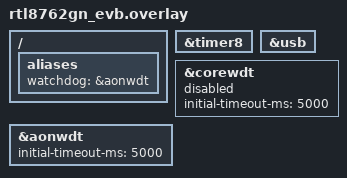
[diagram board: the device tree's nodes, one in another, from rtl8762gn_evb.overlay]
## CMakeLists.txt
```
# SPDX-License-Identifier: Apache-2.0

cmake_minimum_required(VERSION 3.20.0)
find_package(Zephyr REQUIRED HINTS $ENV{ZEPHYR_BASE})
project(ppt_dongle)

FILE(GLOB app_sources src/*.c)
list(REMOVE_ITEM app_sources ${CMAKE_CURRENT_SOURCE_DIR}/src/dongle_ppt_trans_handle.c)
FILE(GLOB usb_sources src/usb/*.c)

target_sources(app PRIVATE ${app_sources})
target_sources(app PRIVATE ${usb_sources})

target_include_directories(app PRIVATE inc)
target_include_directories(app PRIVATE src)
target_include_directories(app PRIVATE src/usb)
```

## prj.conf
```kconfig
CONFIG_BT=y
CONFIG_REALTEK_PPT=y
CONFIG_PWM=y
CONFIG_COUNTER=y

CONFIG_USB_DEVICE_STACK=y
CONFIG_USB_DEVICE_HID=y
CONFIG_USB_DEVICE_PRODUCT="Zephyr HID sample"
CONFIG_USB_DEVICE_PID=0x0006
CONFIG_USB_HID_BOOT_PROTOCOL=y
CONFIG_USB_DEVICE_INITIALIZE_AT_BOOT=n
CONFIG_WATCHDOG=y
CONFIG_REALTEK_USING_SDK_LIB=y
CONFIG_REALTEK_USING_PPT_SYNC_MASTER=n
CONFIG_REALTEK_USING_PPT_SYNC_SLAVE=y

CONFIG_FLASH=y
CONFIG_FLASH_PAGE_LAYOUT=y
CONFIG_FLASH_MAP=y
CONFIG_NVS=y
CONFIG_SETTINGS=y

CONFIG_LOG=y
```

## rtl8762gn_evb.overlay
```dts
/ {
	aliases {
        watchdog = &aonwdt;
    };
};

&timer8 {
    status = "okay";
};

&usb {
    status = "okay";
};

&corewdt {
    status = "disabled";
    initial-timeout-ms = <5000>;
};

&aonwdt {
    status = "okay";
    initial-timeout-ms = <5000>;
};
```

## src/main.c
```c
/*
 * Copyright (c) 2025 Realtek Semiconductor Corp.
 *
 * SPDX-License-Identifier: Apache-2.0
 */

#include <zephyr/kernel.h>
#include <zephyr/logging/log.h>
#if FEATURE_SUPPORT_PROPRIETARY_TRANSPORT
#include "dongle_ppt_trans_handle.h"
#endif
#if PPT_TRANS_FEATURE_SUPPORT_POS_CTRL
#include "ppt_trans_pos_ctrl.h"
#endif
#include "trace.h"

LOG_MODULE_REGISTER(ppt_dongle, 4);

static void global_data_init(void)
{
    app_init_ppt_global_data();
}

int main(void) {
	LOG_DBG("main");
	DBG_DIRECT("MAIN");
	global_data_init();
	dongle_ppt_init();
	dongle_ppt_enable();
}
```

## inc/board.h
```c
/**
*********************************************************************************************************
*               Copyright(c) 2015, Realtek Semiconductor Corporation. All rights reserved.
*********************************************************************************************************
* @file      board.h
* @brief     header file of ppt dongle demo.
* @details
* @author
* @date      2025-09-23
* @version   v0.1
* *********************************************************************************************************
*/


#ifndef _BOARD_H_
#define _BOARD_H_

#ifdef __cplusplus
extern "C" {
#endif

#include "rtl_pinmux.h"

/*******************************************************
*                 Log Config
*******************************************************/
#define IS_RELEASE_VERSION      0   /* 1: close log    0: open log */

#define ENABLE_2_4G_LOG         0   /* 0: close log    1: open log */
#define BUTTON_PRINT_LOG        0   /* 0: close log    1: open log */

#define ENABLE_FULL_FEATURED_DIRECT_LOG     1

/*******************************************************
*                 2.4g Feature Config
*******************************************************/
#define PPT_PAIR_ACC                                            0x8EBE89D6

#define FEATURE_SUPPORT_APP_CFG_PPT_TX_POWER                    0  /* set 1 to use tx power that app config for ppt */
#define FEATURE_SUPPORT_PPT_QUEUE_SEND                          0  /* set 1 to enable ppt queue send strategy*/

/*******************************************************
*                 Dongle Repair Config
*******************************************************/
#define NOT_ALLOW_TO_REPAIR                             1
#define ALLOW_TO_REPAIR_WITHIN_LIMITED_TIME_AFTER_RESET 2

#define DONGLE_REPAIR_MODE  ALLOW_TO_REPAIR_WITHIN_LIMITED_TIME_AFTER_RESET

/*******************************************************
*                 USB Feature Config
*******************************************************/
#define FEATURE_SUPPORT_USB_FORCE_WAKE_UP_HOST                  1  /* set 1 to enable device force wake up host */
#define FEATURE_ALWAYS_IN_USB_MODE_WHEN_USB_INSET               1  /* set 1 to use usb mode when usb inset */

#endif /* _BOARD_H_ */
```

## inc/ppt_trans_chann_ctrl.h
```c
/**
*****************************************************************************************
*     Copyright(c) 2024, Realtek Semiconductor Corporation. All rights reserved.
*****************************************************************************************
   * @file      ppt_trans_chann_ctrl.h
   * @brief     proprietary transport layer channel control sub-module
   * @author
   * @date
   * @version   v1.0
   **************************************************************************************
   * @attention
   * <h2><center>&copy; COPYRIGHT 2024 Realtek Semiconductor Corporation</center></h2>
   **************************************************************************************
  */

#ifndef __PPT_TRANS_CHANN_CTRL_H__
#define __PPT_TRANS_CHANN_CTRL_H__

#ifdef __cplusplus
extern "C"  {
#endif      /* __cplusplus */

/*============================================================================*
 *                              Header Files
 *============================================================================*/
#include "stdint.h"
#include "ppt_trans_handle.h"


/** @defgroup CHANNEL_CONTROL CHANNEL_CONTROL
  * @brief
  * @{
  */

/*============================================================================*
 *                              Definitions
 *============================================================================*/
/** @defgroup CHANNEL_CONTROL_Exported_Macros CHANNEL_CONTROL Exported Macros
 * @brief
 * @{
 */
/*Channel Control define Start Example*/
/*This parameter determines the interval at which the channel monitor is triggered.
It defines the duration, measured in milliseconds, between each activation of the channel monitor.*/
#define PPT_TRANS_CHANN_MONITOR_ITVL              1000

/*This parameter defines the minimum duration for channel usage in the channel control module.
It determines the amount of time the channel should be utilized after executing channel hopping.
The unit of measurement for this parameter is milliseconds.*/
#define PPT_TRANS_MIN_CHANN_USAGE_TIME            (2 * 1000)

/*This define the trigger threshold for the channel monitor. The parameter determines
the minimum acceptable ACK receive rate for the 2.4G packet transmission. This threshold
is defined as a percentage value. For example, if the trigger threshold is set to 98%, it
means that the 2.4G packet transmission system expects to receive at least 98% of the
ACKs from the 2.4G slave device. To put it in perspective, if 7000 packets are sent, the
system would expect to receive a minimum of 6860 ACKs.

By setting a higher trigger threshold, the system becomes more sensitive to the
environment and demands a higher success rate in terms of ACK reception. This can help
ensure a more reliable and efficient 2.4G packet transmission by minimizing the chances
of packet loss or interference. */
#define CHANN_MONITOR_CHANN_SWEEP_THRESH   95

/*This define the channel disqualify trigger counts threshold for the channel monitor. The
parameter determines the number of consecutive failures to meet the ACK receive rate
trigger threshold before a channel is viewed as disqualified. This threshold is specified by
a count value.

For example, if the disqualify trigger counts threshold is set to 3, it means that if a
channel fails to meet the ACK receive rate trigger threshold for 3 consecutive times, the
channel monitor will consider the channel disqualified and will execute channel sweeping to
select a new channel.

By setting a lower disqualify trigger counts threshold, the system will become more
sensitive to the environment and reacts quickly to unfavorable channel conditions.*/
#define SWEEP_TRIGGER_THRESH_COUNT         3

/*The parameter determines the duration for which the monitor scans and evaluates each
available channel during the sweeping operation. Users can adjust this duration based on
the size of the network and the time required for accurate channel analysis. The
parameter is defined in milliseconds.

For example, if the parameter is set to 200 milliseconds, it means that the channel
monitor will sample and evaluate each channel candidate for a period of 200 milliseconds.
During this time, the monitor collects statistical data and performance metrics for analysis
and decision-making.

By setting a larger value for the total accumulated time, the channel sweeping process will
take more time as each channel is evaluated for a longer duration. This can result in a
higher level of accuracy and reliability in determining the performance of each channel.*/
#define PER_CHANNEL_SWEEPING_TIME          200

/*The definition of this parameter is same as previous. The difference is that this
parameter is only used when the master and slave are performing reconnection*/
#define PER_RECONN_CHANNEL_SWEEPING_TIME   100

/*The definition of this parameter is same as previous. The difference is that this
parameter is only used when the master and slave first connected.*/
#define PER_CONN_CHANNEL_SWEEPING_TIME     500
/*Channel Control define End Example*/
/*Connect Sweep define Start Example*/
/*This define the lenth of the paratial set of the channel candidate. For example, by
setting the parameter to 4, the channel sweeping module will maintain a partial set
consisting of the best 4 channels. These channels will be considered as the channel
candidates when the 2.4GHz connection is lost and needs to be reestablished. The length
value shall smaller than the length of the full set channel candidates.
*/
#define LOST_RECONN_SWEEP_CHANN_LEN        4

/*This define the time threshold for channel monitor whether to use the partial set of the
channal candidates of not, the unit is define in milliseconds. For example, by setting the
parameters to 1500. When connected if the time delta since last disconnect is below 1500
ms, it may indicate that the environment has not changed significantly since the previous
connection, and the previous channel sweep result can be reused.*/
#define CONSIDER_LOST_DURATION             1500
/*Connect Sweep define End Example*/
/*Bad Environment define Start Example*/
/* These two parameters, BAD_ENVIRONMENT_MONITOR_TIME and
CONSIDER_BAD_ENVIRONMENT, work together to define the condition for rapid triggering.
BAD_ENVIRONMENT_MONITOR_TIME is defined in seconds and represents the time interval
within which the channel sweep triggers are monitored. It determines the duration over
which the channel sweep trigger count is evaluated.
CONSIDER_BAD_ENVIRONMENT is defined in count and represents the threshold for the
number of channel sweep triggers within the specified time interval. If the channel sweep
is triggered equal to or more than the specified count within the defined time interval, the
condition of rapid triggering is considered to be met.
For example, if the parameters are set to 20 seconds and 3 times, it means that the
channel sweep triggers are monitored within a 20-second interval. If the channel sweep is
triggered 3 times or more within this 20-second interval, it is considered to be a rapid
triggering condition and the module will lower the channel sweeping trigger threshold for
chaotic environment protection.
*/
#define BAD_ENVIRONMENT_MONITOR_TIME       20 //seconds
#define CONSIDER_BAD_ENVIRONMENT           3

/*The parameter determines the duration for which the channel monitor will lower the
channel sweeping trigger threshold when rapid triggering is detected. It is defined in
milliseconds.
For example, if you set the parameter to 60000 milliseconds (60 seconds), it means that
when the channel sweep is triggered rapidly and the condition for rapid triggering is met,
the channel monitor will lower the channel sweeping trigger threshold for a duration of 60
seconds.
*/
#define BAD_ENVIRONMENT_PROTECT_TIME       60000

/*The definition of this parameter is same as SWEEP_TRIGGER_THRESH_COUNT and is the
trigger criteria for chaotic environment.
*/
#define BAD_EVN_SWEEP_TRIGGER_THRESH       5

/*The definition of this parameter is same as CHANN_MONITOR_CHANN_SWEEP_THRESH
and is the trigger criteria for chaotic environment.
*/
#define BAD_EVN_CHANN_SWEEP_THRESH         90
/*Bad Environment define End Example*/
/*Channel Delta define Start Example*/
/* This parameter determines the minimn channel bandwidth delta with the emergency
channel and the main channel. For example if the main channel is 2442 (MHz) than the
emergency channel should greater than 2467 (Mhz) or lesser than 2417 (MHz)
*/
#define EMERGENCY_CAHNNEL_MIN_DELTA        25
/*Channel Delta define End Example*/
/** End of CHANNEL_CONTROL_Exported_Macros
  * @}
  */
/*============================================================================*
 *                              Functions
 *============================================================================*/
/** @defgroup CHANNEL_CONTROL_Exported_Functions CHANNEL_CONTROL Exported Functions
 * @brief
 * @{
 */
/*Code Section Start Example*/
/**
 * @brief  channel control module init, shall only called by 2.4G master.
 * @return none
 */
void ppt_trans_chann_ctrl_master_init(void);

/**
 * @brief  channel control module init, shall only called by 2.4G slave
 * @return none
 */
void ppt_trans_chann_ctrl_slave_init(void);

/**
 * @brief   command 2.4G master to perfoem channel sweep.
 * @param   len        - length of the channel index array
 * @param   chan_idx   - pointer of the channel index array
 * @param   sweep_time - period of time for each channel
 * @return  command success or fail
 * @retval  true    command success
 * @retval  false   command fail
 */
bool ppt_trans_chann_ctrl_command_sweep_channel(uint8_t len, uint8_t *chan_idx,
                                                uint16_t sweep_time);

/**
 * @brief   this api will process the statistic result of each channel when channel sweeping
 *          complete.
 * @param   param - the statistic result for each channel candidate
 * @return  none
 */
void ppt_trans_chann_ctrl_get_result(sync_chann_param_t param);

/**
 * @brief   handle channel control module when 2.4G master and slave disconnected.
 * @return  none
 */
void ppt_trans_chann_ctrl_handle_disconnect(void);

/**
 * @brief   handle channel control module when 2.4G master and slave connected.
 * @return  none
 */
void ppt_trans_chann_ctrl_handle_connect(void);

/**
 * @brief   To get whether 2.4G device is performing channel sweeping.
 * @return  channel sweeping status
 * @retval  true   no channel sweeping ongoing
 * @retval  false  channel sweeping ongoing
 */
bool ppt_trans_chann_ctrl_is_idle(void);

/**
 * @brief   ACK count statistic for channel monitor.
 * @return  none
 */
void ppt_trans_chann_ctrl_ack_cnt_inc(void);

/**
 * @brief   NACK count statistic for channel monitor.
 * @return  none
 */
void ppt_trans_chann_ctrl_nack_cnt_inc(void);

/**
 * @brief   Send fail count statistic for channel monitor.
 * @return  none
 */
void ppt_trans_chann_ctrl_send_fail_cnt_inc(void);

/**
* @brief   Declared for long packet module, will be referenced
*          when channel control long packet reception completes.
* @param   result   - long packet receive status.
* @param   pkt_data - pointer of received long packet data.
* @param   len      - length of received long packet data
* @param   info     - 2.4G related info.
* @return  none
*/
void ppt_tans_chann_ctrl_long_pkt_rcv_cb(bool result, uint8_t *pkt_data, uint16_t len,
                                         sync_receive_info_t info);

/**
 * @brief   handle channel control module when 2.4G slave disconnect with master,
 *          shall only be called by 2.4G slave.
 * @return  none
 */
void ppt_trans_chann_ctrl_slave_handle_disconnect(void);
/*Code Section End Example*/
/** End of CHANNEL_CONTROL_Exported_Functions
  * @}
  */

/** End of CHANNEL_CONTROL
  * @}
  */

#ifdef __cplusplus
}
#endif      /* __cplusplus */

#endif // __PPT_8K_TRANS_LONG_PKT_CTRL_H__
```

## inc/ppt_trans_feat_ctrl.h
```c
/**
*****************************************************************************************
*     Copyright(c) 2024, Realtek Semiconductor Corporation. All rights reserved.
*****************************************************************************************
   * @file      ppt_trans_feat_ctrl.h
   * @brief     proprietary transport layer transport layer feature controlling sub-module
   * @author    luke
   * @date      2024-05-15
   * @version   v1.0
   **************************************************************************************
   * @attention
   * <h2><center>&copy; COPYRIGHT 2024 Realtek Semiconductor Corporation</center></h2>
   **************************************************************************************
   */

#ifndef __PPT_TRANS_FEAT_CTRL_H__
#define __PPT_TRANS_FEAT_CTRL_H__

#ifdef __cplusplus
extern "C" {
#endif

/*============================================================================*
 *                              Header Files
 *============================================================================*/
#include "ppt_trans_handle.h"


/*============================================================================*
 *                              Defines
 *============================================================================*/


/*============================================================================*
 *                              Functions
 *============================================================================*/
/**
 * @brief initialization of transport feature ctrl sub-module
 *
 * @param feat - feature enable mask
 *               each bit reprepresents enabling/disable an corresponding feature
 *
 */
void ppt_trans_feat_ctrl_init(uint32_t feat);

/**
 * @brief  set specified feature as compatible or incompatible.
 *         used to avoid error when application configure wrong macros
 *
 * @param  feat - feature to be enable or disabled
 * @param  enable - enable specified feature by passing true, disable it by passing false
 */
void ppt_trans_feat_ctrl_set_feature_compatible(T_PPT_TRANS_FEATURES feat, bool enable);

/**
 * @brief  enable or disable specified feature
 *
 * @param  feat - feature to be enable or disabled
 * @param  enable - enable specified feature by passing true, disable it by passing false
 */
void ppt_trans_feat_ctrl_set_feature_status(T_PPT_TRANS_FEATURES feat, bool enable);

/**
 * @brief  get specified feature enable status
 *
 * @param  feat - feature to be checked
 * @return bool - true -> feature enabled
 *                false -> feature disabled
 */
bool ppt_trans_feat_ctrl_get_feature_status(T_PPT_TRANS_FEATURES feat);

#ifdef __cplusplus
}
#endif

#endif // __PPT_TRANS_FEAT_CTRL_H__
```

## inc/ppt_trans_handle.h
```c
/**
*****************************************************************************************
*     Copyright(c) 2023, Realtek Semiconductor Corporation. All rights reserved.
*****************************************************************************************
   * @file      ppt_trans_handle.h
   * @brief     proprietary transport layer interface to application
   * @author    luke
   * @date      2023-09-28
   * @version   v1.0
   **************************************************************************************
   * @attention
   * <h2><center>&copy; COPYRIGHT 2018 Realtek Semiconductor Corporation</center></h2>
   **************************************************************************************
  */
#ifndef __PPT_TRANS_HANDLE_H__
#define __PPT_TRANS_HANDLE_H__

#ifdef __cplusplus
extern "C"  {
#endif      /* __cplusplus */

/*============================================================================*
 *                              Header Files
 *============================================================================*/
#include "rtl876x.h"
#include "ppt_sync.h"

#define PPT_TRANSPORT_VERSION                       "v1.2.2"
/*============================================================================*
 *                    Transport Layer Feature Control Macros
 *============================================================================*/
#define PPT_TRANS_FEATURE_TRANSPORT_EN              1       /** Enable transport layer send/receive or not */
#define PPT_TRANS_FEATURE_PKT_RETRANS_EN            1       /** Enable mouse packet retransmission */
#define PPT_TRANS_FEATURE_ADP_RPT_RATE_EN           0       /** Enable adaptive report rate change */

#if FEATURE_SUPPORT_PROPRIETARY_HOPPING
#define PPT_TRANS_FEATURE_CONFIG_CHAN               1       /** Enable configure channel by transport layer */
/*Channel Sweep Enable Start Example*/
#define PPT_TRANS_FEATURE_SUPPORT_CHANNEL_CTRL      0       /** Enable channel statistic control method */
/*Channel Sweep Enable End Example*/
/*Channel Traverse Enable Start Example*/
#define PPT_TRANS_FEATURE_SUPPORT_CHANNEL_TRAVERSE  1       /** Enable channel travese control method */
/*Channel Traverse Enable End Example*/
#define PPT_TRANS_FEATURE_SUPPORT_16BITS_MOV        1       /** Enable 16btis movement data */
#define PPT_TRANS_FEATURE_SUPPORT_POS_CTRL          1       /** Enable position control feature*/
#define PPT_TRANS_FEATURE_SUPPORT_PAIRING_ID        0       /** Enable configure pairing ID by application */
#else
#define PPT_TRANS_FEATURE_CONFIG_CHAN               0       /** Enable configure channel by transport layer */
#define PPT_TRANS_FEATURE_SUPPORT_CHANNEL_CTRL      0       /** Enable syncing cursor offset */
#define PPT_TRANS_FEATURE_SUPPORT_CHANNEL_TRAVERSE  0       /** Enable channel travese control method */
#define PPT_TRANS_FEATURE_SUPPORT_16BITS_MOV        1       /** Enable 16btis movement data */
#define PPT_TRANS_FEATURE_SUPPORT_POS_CTRL          1       /** Enable position control feature*/
#define PPT_TRANS_FEATURE_SUPPORT_PAIRING_ID        0       /** Enable configure pairing ID by application */
#endif

/*Channel Limit Start Example*/
#if PPT_TRANS_FEATURE_SUPPORT_CHANNEL_CTRL && PPT_TRANS_FEATURE_SUPPORT_CHANNEL_TRAVERSE
#error "Cannot enable both feature simutaniously"
#endif
/*Channel Limit End Example*/
/*============================================================================*
 *                              Sync Control Macros
 *============================================================================*/
#define PPT_REPORT_RATE_LEVEL_8K                    8000
#define PPT_REPORT_RATE_LEVEL_4K                    4000
#define PPT_REPORT_RATE_LEVEL_2K                    2000
#define PPT_REPORT_RATE_LEVEL_1K                    1000

/** if no external data from application within this time of period,
 *  Transport layer will change to idle state and check if all packet sending completed (ex. channel sweep, long packet) */
#define PPT_TRANS_SYNC_CTRL_REPORT_IDLE_ITVL        50 // ms

#if PPT_TRANS_FEATURE_CONFIG_CHAN
#if PPT_TRANS_FEATURE_SUPPORT_CHANNEL_TRAVERSE
#define PPT_TRANS_SYNC_CHANS                        2450, 2412, 2437, 2423, 2479, 2428, 2462, 2404, 2442
#else
#define PPT_TRANS_SYNC_CHANS                        2450, 2404, 2477, 2412, 2467, 2437, 2423, 2457, 2479, 2428, 2462, 2425, 2447, 2405, 2442
#endif
#endif

#if PPT_TRANS_FEATURE_ADP_RPT_RATE_EN
/** history packets checked, non changable */
#define PPT_WATCH_HIST_PKT_CNT                  96
/** criterion to increase report rate */
#define PPT_INC_RPT_RATE_CNT                    95
/** criterion to decrease report rate */
#define PPT_DEC_RPT_RATE_CNT                    50
/** disable report rate change for this period, unit ms */
#define PPT_ADP_RPT_GUARD_TIME                  6000
#endif

#if PPT_TRANS_FEATURE_PKT_RETRANS_EN
/** size of the history data list to store failed mouse data */
#define PPT_FAIL_PKT_LIST_SIZE                  16
#endif

/*============================================================================*
 *                              Packet Control Macros
 *============================================================================*/
/** Size of history packets stored */
#define PPT_PKT_HIST_PKT_SIZE                   16
/** Size of missed wheel data stored */
#define PPT_PKT_HIST_WHEEL_ARR_SIZE             64
/** Flush pkt ctrl buffer if link lost and didn't reconnect afterwards, unit: ms */
#define PPT_PKT_LINK_LOST_FLUSH_TIME            500

/** Size of each packet payload from master to slave, unit: bytes */
#define PPT_PKT_8K_M2S_PAYLOAD_SIZE_MAX         7
#define PPT_PKT_4K_M2S_PAYLOAD_SIZE_MAX         12
#define PPT_PKT_2K_M2S_PAYLOAD_SIZE_MAX         20
#define PPT_PKT_1K_M2S_PAYLOAD_SIZE_MAX         30

/** Size of each packet payload from slave to master, unit: bytes */
#define PPT_PKT_8K_S2M_PAYLOAD_SIZE_MAX         3
#define PPT_PKT_4K_S2M_PAYLOAD_SIZE_MAX         12
#define PPT_PKT_2K_S2M_PAYLOAD_SIZE_MAX         20
#define PPT_PKT_1K_S2M_PAYLOAD_SIZE_MAX         30

/*============================================================================*
 *                              Packet Algorithm Macros
 *============================================================================*/
/** Size of each field contained in packet header, unit: bits */
#define PPT_PKT_HDR_SIZE_SEQ_EN                 1
#define PPT_PKT_HDR_SIZE_BUTTON_EN              1
#define PPT_PKT_HDR_SIZE_WHEEL_EN               1
#define PPT_PKT_HDR_SIZE_MOTION_EN              3
#define PPT_PKT_HDR_SIZE_LONG_PKT_EN            1
#define PPT_PKT_HDR_SIZE_PKT_TYPE               1
#define PPT_PKT_HDR_SIZE_RSVD                   1

/** Size of each field contained in packet payload, unit: bits */
#define PPT_PKT_PAYLOAD_SIZE_HEADER             8
#define PPT_PKT_PAYLOAD_SIZE_SEQ                6
#define PPT_PKT_PAYLOAD_SIZE_BUTTON             7
#define PPT_PKT_PAYLOAD_SIZE_WHEEL              3

/** MAX numbers of each mouse data carried in a payload */
#define PPT_PKT_PAYLOAD_DATA_NUM_MAX_DV         2
#define PPT_PKT_8K_PAYLOAD_DATA_NUM_MAX_DV      2

/** Numbers of all possible sequence number */
#define PPT_PKT_PAYLOAD_SEQ_NUM_SIZE            BIT(PPT_PKT_PAYLOAD_SIZE_SEQ)

/*============================================================================*
 *                              Transport layer configuration Macros
 *============================================================================*/
#define PPT_PKT_PAYLOAD_DATA_NUM_MAX            ppt_trans_handle_cfg_mgr.ppt_max_pkt_mouse_data_num

/*============================================================================*
 *                              Debug Macros
 *============================================================================*/
/** DBG LOG control macro */
#define PPT_TRANS_DEBUG_LOG_ENABLE              0
#define PPT_TRANS_HANDLE_DBG_LOG_EN             (0 && PPT_TRANS_DEBUG_LOG_ENABLE)
#define PPT_TRANS_PKT_ALGO_DBG_LOG_EN           (0 && PPT_TRANS_DEBUG_LOG_ENABLE)
#define PPT_TRANS_PKT_CTRL_DBG_LOG_EN           (1 && PPT_TRANS_DEBUG_LOG_ENABLE)
#define PPT_TRANS_LONG_PKT_CTRL_DBG_LOG_EN      (0 && PPT_TRANS_DEBUG_LOG_ENABLE)
#define PPT_TRANS_SYNC_CTRL_DBG_LOG_EN          (0 && PPT_TRANS_DEBUG_LOG_ENABLE)
#define PPT_TRANS_TEST_HANDLE_DBG_LOG_EN        (0 && PPT_TRANS_DEBUG_LOG_ENABLE)
#define PPT_TRANS_TEST_STUB_SYNC_DBG_LOG_EN     (1 && PPT_TRANS_DEBUG_LOG_ENABLE)
#define PPT_TRANS_CHANN_CTRL_DBG_LOG            (0 && PPT_TRANS_DEBUG_LOG_ENABLE)
/** dump packet send status as log */
#define PPT_TRANS_SYNC_CTRL_REPORT_STAT            0
/** interval between each packet send status log */
#define PPT_TRANS_SYNC_CTRL_REPORT_STAT_ITVL       1000

#define PPT_TRANS_DEBUG_PIN_ENABLE                 0

#define PPT_TRANS_GPIO_DEBUG_PIN                  {P3_0, P3_1, P1_0, P1_1}
#define TIME_DEBUG_CHAN_INVALID                 -1
#define TIME_DEBUG_CHAN_TX_SEND                 -1
#define TIME_DEBUG_CHAN_TX_COMPOSE_PKT          -1
#define TIME_DEBUG_CHAN_TX_COMPENSATE           -1
#define TIME_DEBUG_CHAN_TX_CB                   -1
#define TIME_DEBUG_CHAN_TX_SAMPLE               -1
#define TIME_DEBUG_CHAN_TX_FILL                 -1
#define TIME_DEBUG_CHAN_RX_RECV                 -1
#define TIME_DEBUG_CHAN_RX_PARSE                -1
#define TIME_DEBUG_SENSOR_INT                   -1
#define TIME_DEBUG_PPT_TRANSPORT_USB_MSG_SEND   -1

#if PPT_TRANS_DEBUG_PIN_ENABLE

extern uint8_t ppt_trans_debug_pin[];
extern uint32_t ppt_trans_gpio_debug_pin[];
#define PPT_TRANS_GPIO_LEVEL_HIGH(ch)   do \
    { \
        if(ch != TIME_DEBUG_CHAN_INVALID) \
        {\
            GPIOA->GPIO_DR |= ppt_trans_gpio_debug_pin[ch]; \
        }\
    }while(0)
#define PPT_TRANS_GPIO_LEVEL_LOW(ch)    do \
    { \
        if(ch != TIME_DEBUG_CHAN_INVALID) \
        {\
            GPIOA->GPIO_DR &= ~ppt_trans_gpio_debug_pin[ch]; \
        }\
    }while(0)
#define PPT_TRANS_GPIO_EDGE_UP(ch)      do \
    { \
        if(ch != TIME_DEBUG_CHAN_INVALID) \
        {\
            GPIOA->GPIO_DR &= ~ppt_trans_gpio_debug_pin[ch]; \
            GPIOA->GPIO_DR |= ppt_trans_gpio_debug_pin[ch]; \
        }\
    }while(0)
#define PPT_TRANS_GPIO_EDGE_DOWN(ch)      do \
    { \
        if(ch != TIME_DEBUG_CHAN_INVALID) \
        {\
            GPIOA->GPIO_DR |= ppt_trans_gpio_debug_pin[ch]; \
            GPIOA->GPIO_DR &= ~ppt_trans_gpio_debug_pin[ch]; \
        }\
    }while(0)
#else
#define PPT_TRANS_GPIO_LEVEL_HIGH
#define PPT_TRANS_GPIO_LEVEL_LOW
#define PPT_TRANS_GPIO_EDGE_UP
#define PPT_TRANS_GPIO_EDGE_DOWN
#endif
/*============================================================================*
 *                              Typedefs
 *============================================================================*/
/**
 * @brief PPT transport layer module role definition
 *
 */
typedef enum
{
    PPT_TRANS_ROLE_MASTER            = 0,
    PPT_TRANS_ROLE_SLAVE,
} T_PPT_TRANS_ROLES;


typedef enum
{
    PPT_TRANS_APPLICATION_RPT_RATE   = 0,
    PPT_TRANS_APPLICATION_LINK_LOST
} T_PPT_TRANS_APPLICATION_DATA;

/**
 * @brief PPT transport layer ENABLE/DISABLE definition
 *
 */
typedef enum
{
    PPT_TRANS_FIELD_DISABLE          = 0,
    PPT_TRANS_FIELD_ENABLE           = 1
} T_PPT_TRANS_FUNCTIONAL_STATE;

/**
 * @brief PPT transport layer Packet type definition
 *
 */
typedef enum
{
    PPT_TRANS_PKT_TYPE_OFFSET        = 0,
    PPT_TRANS_PKT_TYPE_COMPENSATE    = 1
} T_PPT_TRANS_PACKET_TYPE;

/**
 * @brief  PPT transport layer report rate change request.
 */
typedef enum
{
    PPT_TRANS_INC_REPORT_RATE_REQ        = 0,
    PPT_TRANS_DEC_REPORT_RATE_REQ        = 1,
    PPT_TRANS_FORCE_INC_REPORT_RATE_REQ  = 2,
} T_PPT_TRANS_REPORT_RATE_REQ_TYPE;

/**
 * @brief PPT transport layer module mouse data definition
 *
 */
typedef struct
{
    uint8_t                 wheel_direction;
    uint8_t                 button;
    int16_t                 optical_x;
    int16_t                 optical_y;
} T_PPT_TRANS_MOUSE_DATA;

/**
 * @brief PPT transport layer motion data size definition
 *
 */
typedef enum
{
    PPT_TRANS_MOTION_SIZE_0BITS = 0,
    PPT_TRANS_MOTION_SIZE_2BITS,
    PPT_TRANS_MOTION_SIZE_4BITS,
    PPT_TRANS_MOTION_SIZE_8BITS,
    PPT_TRANS_MOTION_SIZE_16BITS
} T_PPT_TRANS_MOTION_DATA_SIZE;

/**
 * @brief PPT transport layer wheel direction definition
 *
 */
typedef enum
{
    PPT_TRANS_WHEEL_RELEASE_DEF  = 0x0,
    PPT_TRANS_WHEEL_V_UP_DEF,
    PPT_TRANS_WHEEL_V_DOWN_DEF,
    PPT_TRANS_WHEEL_H_UP_DEF,
    PPT_TRANS_WHEEL_H_DOWN_DEF,
} T_PPT_TRANS_WHEEL_DIRECTION;

/**
 * @brief PPT transport layer feature list
 *
 */
typedef enum
{
    T_PPT_TRANS_FEAT_CTRL_FEATURE_TRANSPORT      = 0,    /** enable transport layer or not */
    T_PPT_TRANS_FEAT_CTRL_FEATURE_PKT_RETRANS,
    T_PPT_TRANS_FEAT_CTRL_FEATURE_ADP_RATE,
    T_PPT_TRANS_FEAT_CTRL_FEATURE_CONFIG_CHAN,
    T_PPT_TRANS_FEAT_CTRL_FEATURE_CHAN_CTRL,
    T_PPT_TRANS_FEAT_CTRL_FEATURE_POS_CTRL,
    T_PPT_TRANS_FEAT_CTRL_FEATURE_16BITS_MOV,
    T_PPT_TRANS_FEAT_CTRL_FEATURE_PAIRING_ID,

    T_PPT_TRANS_FEAT_CTRL_DEBUG_REPORT_STAT,

    T_PPT_TRANS_FEAT_CTRL_FEATURE_NUM
} T_PPT_TRANS_FEATURES;


/**
 * @brief PPT transport layer packet header definition
 *
 */
typedef union _T_PPT_TRANS_PKT_HEADER
{
    struct
    {
uint8_t long_pkt_en : PPT_PKT_HDR_SIZE_LONG_PKT_EN;
uint8_t motion_size : PPT_PKT_HDR_SIZE_MOTION_EN;
uint8_t wheel_en    : PPT_PKT_HDR_SIZE_WHEEL_EN;
uint8_t button_en   : PPT_PKT_HDR_SIZE_BUTTON_EN;
uint8_t pkt_type    : PPT_PKT_HDR_SIZE_PKT_TYPE;
uint8_t seq_en      : PPT_PKT_HDR_SIZE_SEQ_EN;
    };
    uint8_t d8;
} T_PPT_TRANS_PKT_HEADER;

typedef struct
{
    uint8_t                 wheel_direction;
    uint8_t                 button;
    int32_t                 optical_x;
    int32_t                 optical_y;
} T_PPT_MOUSE_ABS_POS_DATA;

typedef void (*ppt_trans_handle_receive_pos_pkt_cb)(T_PPT_MOUSE_ABS_POS_DATA *data, uint8_t len,
                                                    uint8_t seq_num);
typedef void (*ppt_trans_handle_algo_compose_pos)(T_PPT_TRANS_MOUSE_DATA *data_src,
                                                  uint8_t length_src,
                                                  uint8_t *data_pos_in, uint8_t len_pos,
                                                  uint8_t *data_out, uint8_t *length_out, uint8_t seq_num);
typedef void (*ppt_trans_handle_algo_parse_pos)(uint8_t *data_src, uint16_t length_src,
                                                uint8_t *pos_out, uint16_t length_pos,
                                                T_PPT_TRANS_MOUSE_DATA *but_out, uint8_t *length_out,
                                                uint8_t *seq_num);

typedef void (*ppt_trans_handle_long_pkt_send_compl_cb)(bool result, sync_send_info_t info);
typedef void (*ppt_trans_handle_long_pkt_recv_compl_cb)(bool result, uint8_t *pkt_data,
                                                        uint16_t len, sync_receive_info_t info);
typedef void (*ppt_trans_handle_receive_pkt_cb)(T_PPT_TRANS_MOUSE_DATA *data, uint8_t len,
                                                uint8_t seq_num);
typedef bool (*ppt_trans_handle_receive_raw_cb)(uint8_t *p_data, uint16_t len,
                                                sync_receive_info_t *info);
typedef bool (*ppt_trans_handle_get_application_data)(T_PPT_TRANS_APPLICATION_DATA request,
                                                      void *data, uint16_t *len);

typedef void (*ppt_trans_handle_set_sample_rate)(T_PPT_TRANS_REPORT_RATE_REQ_TYPE dir);

typedef struct _T_PPT_TRANS_INIT_TYPEDEF
{
    T_PPT_TRANS_ROLES                           ppt_trans_role;
    ppt_trans_handle_get_application_data       ppt_trans_app_req_handler;
    ppt_trans_handle_set_sample_rate            ppt_trans_app_sample_rate_handler;
#if PPT_TRANS_FEATURE_SUPPORT_POS_CTRL
    ppt_trans_handle_receive_pos_pkt_cb         ppt_trans_app_pos_rx_handler;
    ppt_trans_handle_algo_compose_pos           ppt_trans_algo_compose_pos_handler;
    ppt_trans_handle_algo_parse_pos             ppt_trans_algo_parse_pos_handler;
#endif
    ppt_trans_handle_receive_pkt_cb             ppt_trans_app_rx_handler;
    ppt_trans_handle_receive_raw_cb             ppt_trans_app_rx_raw_handler;
    uint32_t                                    report_rate;
    uint32_t                                    ppt_trans_app_feature_mask;
    uint8_t                                     ppt_max_pkt_size_sent;
    uint8_t                                     ppt_max_pkt_size_recv;
    uint8_t                                     ppt_max_pkt_mouse_data_num;
} T_PPT_TRANS_INIT_TYPEDEF;

extern T_PPT_TRANS_INIT_TYPEDEF ppt_trans_handle_cfg_mgr;

/*============================================================================*
 *                              Functions
 *============================================================================*/
/**
 * @brief initialization of transport layer module
 *
 */
void ppt_trans_handle_init(T_PPT_TRANS_INIT_TYPEDEF *init_typedef);

/**
 * @brief initialize ppt transport layer configuration
 *
 * @param init_typedef - config structure
 */
void ppt_trans_handle_struct_init(T_PPT_TRANS_INIT_TYPEDEF *init_typedef);

/**
 * @brief
 *
 * @param event
 */
void ppt_trans_handle_sync_event_cb_hook(sync_event_t event);

/**
 * @brief update report rate according to different mouse model
 *
 * @param dir increase or decrease report rate
 */
void ppt_trans_handle_report_rate_change(T_PPT_TRANS_REPORT_RATE_REQ_TYPE dir);

/**
 * @brief record sampled trajectory data
 *
 * @param mouse_data sampled SPI data
 */
void ppt_trans_handle_sample_data(T_PPT_TRANS_MOUSE_DATA mouse_data);

/**
 * @brief return current status of transport layer
 *
 * @return - true if transport layer doesnot have pkt to send, otherwise false
 * @retval - bool
 */
bool ppt_trans_handle_transport_status_get(void);

/**
 * @brief handle long packet sending
 *
 * @param long_pkt_src - pointer to long packet
 * @param length - packet length
 * @param req_attempt - attempt to send long packet right after reg sending.
 * @param cb - callback function when long packet transmission completes
 *
 * @note  application layer must keep the buffer alive while processing it
 */
bool ppt_trans_handle_long_pkt_send(uint8_t *long_pkt_src, uint16_t length, bool req_attempt,
                                    ppt_trans_handle_long_pkt_send_compl_cb cb);

/**
 * @brief register long packet receiving handler
 *
 * @param cb - callback function when long packet receiption completes
 *
 */
void ppt_trans_handle_long_pkt_recv(ppt_trans_handle_long_pkt_recv_compl_cb cb);

/**
 * @brief register packet receive app handler
 *
 * @param cb - callback function when any packet is received
 *
 * @note  application layer must store the code section of the handler in RAM section by decorator RAM_FUNCTION
 */
void ppt_trans_handle_reg_pkt_receiver(ppt_trans_handle_receive_pkt_cb cb);

/**
 * @brief register raw data receive app handler
 *
 * @param cb - callback function when any raw data is received
 *             return true if data doesn't require transport layer processing
 *
 * @note  application layer must store the code section of the handler in RAM section by decorator RAM_FUNCTION
 */
void ppt_trans_handle_reg_raw_receiver(ppt_trans_handle_receive_raw_cb cb);

/**
 * @brief register position packet receive app handler
 *
 * @param cb - callback function when any packet is received
 *
 * @note  application layer must store the code section of the handler in RAM section by decorator RAM_FUNCTION
 */
void ppt_trans_handle_reg_pos_pkt_receiver(ppt_trans_handle_receive_pos_pkt_cb cb);

/**
 * @brief notify that application will start/stop continuous sending data
 *
 */
void ppt_trans_handle_notify_continuous_send(bool new_status);

/**
 * @brief  get specified feature enable status
 *
 * @param  feat - feature to be checked
 * @return bool - true -> feature enabled
 *                false -> feature disabled
 */
bool ppt_trans_handle_get_feature_status(T_PPT_TRANS_FEATURES feat);


/**
 * @brief  get specified feature enable status
 *
 * @param  feat - feature to be checked
 * @param  enable - true -> feature enabled
 *                  false -> feature disabled
 */
void ppt_trans_handle_set_feature_status(T_PPT_TRANS_FEATURES feat, bool enable);

/**
 * @brief get optical sensor working status
 *
 */
bool ppt_trans_handle_get_sensor_status(void);

/**
 * @brief get pair id used for sync layer
 *
 * @param  pair_id - pair id to be passed to be set
 * @return bool - true -> pair id successfully get
 *              - false -> pair id had failed to get
 */
bool ppt_trans_handle_get_pair_id(uint32_t *pair_id);


/**
 * @brief configure pair id from application layer
 *
 * @param  pair_id - pair id to be passed to be set
 * @return bool - true -> pair id successfully set
 *              - false -> pair id had failed to set
 */
bool ppt_trans_handle_set_pair_id(uint32_t pair_id);

#ifdef __cplusplus
}
#endif      /* __cplusplus */

#endif // __PPT_TRANS_HANDLE_H__
```

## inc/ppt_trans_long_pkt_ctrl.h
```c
/**
*****************************************************************************************
*     Copyright(c) 2023, Realtek Semiconductor Corporation. All rights reserved.
*****************************************************************************************
   * @file      ppt_trans_long_pkt_ctrl.h
   * @brief     proprietary transport layer long packet data sub-module
   * @author
   * @date
   * @version   v1.0
   **************************************************************************************
   * @attention
   * <h2><center>&copy; COPYRIGHT 2018 Realtek Semiconductor Corporation</center></h2>
   **************************************************************************************
  */

#ifndef __PPT_TRANS_LONG_PKT_CTRL_H__
#define __PPT_TRANS_LONG_PKT_CTRL_H__

#ifdef __cplusplus
extern "C"  {
#endif      /* __cplusplus */

/*============================================================================*
 *                              Header Files
 *============================================================================*/
#include "stdint.h"
#include "ppt_trans_handle.h"


/*============================================================================*
 *                              Definitions
 *============================================================================*/

#define RCV_PKT_TABLE_MAX_LEN       128 // include length of CRC
#define SEND_PKT_TABLE_MAX_LEN      100


#define LONG_PKT_TYPE_FIRST_AND_END 0b00
#define LONG_PKT_TYPE_FIRST_PKT     0b01
#define LONG_PKT_TYPE_CONT_PKT      0b11
#define LONG_PKT_TYPE_END_PKT       0b10

#define RUNNING_WINDOW_MAX_LEN      32

typedef union _T_LONG_PKT_HEADER
{
    struct
    {
        uint8_t packet_type : 2;
        uint8_t seq : 6;
    };
    uint8_t d8;
} T_LONG_PKT_HEADER;

typedef struct _T_SEND_LONG_PKT_TABLE
{
    bool valid;
    uint8_t seq;
    uint16_t offset;
} T_SEND_LONG_PKT_TABLE;

typedef struct _T_RECV_LONG_PKT_TABLE
{
    bool valid;
    uint8_t seq;
    uint8_t len;
    uint8_t data[PPT_PKT_1K_M2S_PAYLOAD_SIZE_MAX - 1];
} T_RECV_LONG_PKT_TABLE;

typedef struct _T_RECV_REORG_LONG_PKT
{
    uint16_t len;
    uint8_t data[RCV_PKT_TABLE_MAX_LEN];
} T_RECV_REORG_LONG_PKT;

typedef enum
{
    USER_DEFINE_PKT = 0x0000,
    LINK_LAYER_PKT  = 0x0001,
    INVALID_HEADER  = 0xFFFF,
} T_LONG_PKT_TRANSFER_HEADER;

/*============================================================================*
 *                              Functions
 *============================================================================*/

/******************************************************************
 * @brief  init PPT transport layer long packet control & managements
 * @retval void
 */
void ppt_trans_long_pkt_ctrl_init(void);

/******************************************************************
 * @brief  register handler for long packet send completion or flushed
 * @param  pkt_src - pointer to the long packet data
 * @param  pkt_len - size of the long packet
 * @param  cb - callback function when long packet transmission completes
 * @retval void
 */
bool ppt_trans_long_pkt_ctrl_reg_long_pkt_send(uint8_t *pkt_src, uint16_t pkt_len,
                                               ppt_trans_handle_long_pkt_send_compl_cb cb);

/******************************************************************
 * @brief  register handler for long packet receive completion
 * @param  cb - callback function when long packet receiption completes
 * @retval void
 */
void ppt_trans_long_pkt_ctrl_reg_long_pkt_recv(ppt_trans_handle_long_pkt_recv_compl_cb cb);

/******************************************************************
 * @brief  handle long packet composition
 * @param  next_pkt - pointer of current processing packet
 * @param  len - size of current processing packet, unit bytes
 * @retval void
 */
bool ppt_trans_long_pkt_ctrl_get_data(uint8_t *next_pkt, uint8_t *len);

/******************************************************************
 * @brief  handle long packet parsing
 * @param  next_pkt - pointer of current processing packet
 * @param  len - size of , unit bytes
 * @param  info - indicate long packet recvived ce_count
 * @retval void
 */
void ppt_trans_long_pkt_parse_pkt(uint8_t *next_pkt, uint8_t len, sync_receive_info_t info);

/******************************************************************
 * @brief  handler function when packets that contains long pkt data is acked
 * @retval void
 */
void ppt_trans_long_pkt_recv_ack(uint8_t *header, sync_send_info_t info);

/******************************************************************
 * @brief  handle long packet send fail
 * @param  packet - pointer of the failed packet
 * @retval void
 */
void ppt_trans_long_pkt_handle_send_fail(uint8_t *packet);

/******************************************************************
 * @brief  To get whether the device is transmitting long packet or not.
 * @retval bool
 */
bool ppt_trans_long_pkt_get_is_long_pkt_transmmiting(void);

/******************************************************************
 * @brief   handle long packet module when 2.4G master and slave disconnected.
 * @return  none
 * @retval  void
 */
void ppt_trans_long_pkt_handle_connect(void);

/******************************************************************
 * @brief  To send link layer long packet message
 * @param  pkt_src - pointer of the packet
 * @param  pkt_len - size of , unit bytes
 * @param  cb - callback function when long packet send completes
 * @retval void
 */
bool ppt_trans_long_pkt_ctrl_link_layer_long_pkt_send(uint8_t *pkt_src, uint16_t pkt_len,
                                                      ppt_trans_handle_long_pkt_send_compl_cb cb);


#ifdef __cplusplus
}
#endif      /* __cplusplus */

#endif // __PPT_TRANS_LONG_PKT_CTRL_H__
```

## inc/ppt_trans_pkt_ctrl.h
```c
/**
*****************************************************************************************
*     Copyright(c) 2023, Realtek Semiconductor Corporation. All rights reserved.
*****************************************************************************************
   * @file      ppt_trans_pkt_ctrl.h
   * @brief     proprietary transport layer packet data control sub-module
   * @author    luke
   * @date      2023-09-28
   * @version   v1.0
   **************************************************************************************
   * @attention
   * <h2><center>&copy; COPYRIGHT 2018 Realtek Semiconductor Corporation</center></h2>
   **************************************************************************************
  */

#ifndef __PPT_TRANS_PKT_CTRL_H__
#define __PPT_TRANS_PKT_CTRL_H__

#ifdef __cplusplus
extern "C"  {
#endif      /* __cplusplus */

/*============================================================================*
 *                              Header Files
 *============================================================================*/
#include "ppt_trans_handle.h"

/*============================================================================*
 *                              Functions
 *============================================================================*/
/******************************************************************
 * @brief  init transport layer packet control & managements
 * @retval void
 */
void ppt_trans_pkt_ctrl_init(void);

/******************************************************************
 * @brief  Receive mouse data send request from application layer
 * @param  mouse_data - mouse data to store
 * @param  is_dummy - mouse data is dummy or real data
 * @retval void
 */
void ppt_trans_pkt_ctrl_receive_data(T_PPT_TRANS_MOUSE_DATA mouse_data, bool is_dummy);

/******************************************************************
 * @brief  handle sending mouse position compensate data
 * @param  next_pkt - pointer that needs to copy packet data in
 * @param  length - how many bytes are copied in next_pkt
 * @param  wheel_dir - the direction of wheel sent in next_pkt
 * @retval pointer to the packet data to be transmitted
 */
void ppt_trans_pkt_ctrl_get_compensate_data(uint8_t *next_pkt, uint8_t *length, uint8_t *wheel_dir);

/******************************************************************
 * @brief  handle sending mouse offset data
 * @param  next_pkt - pointer that needs to copy packet data in
 * @param  length - how many bytes are copied in next_pkt
 * @param  wheel_dir - the direction of wheel sent in next_pkt
 * @retval pointer to the packet data to be transmitted
 */
void ppt_trans_pkt_ctrl_get_offset_data(uint8_t *next_pkt, uint8_t *length, uint8_t *wheel_dir);

#if PPT_TRANS_FEATURE_PKT_RETRANS_EN
/******************************************************************
 * @brief  handle NACK packet wheel compensation
 * @param  wheel_dir - QDEC direction data
 *
 * @note   handle critical section outside this function
 */
void ppt_trans_pkt_ctrl_report_nack_wheel(uint8_t wheel_dir);

/******************************************************************
 * @brief  clear send fail/nack motion compensation
 */
void ppt_trans_pkt_ctrl_clear_compensate_motion(void);

/******************************************************************
 * @brief  handle NACK packet compensation
 * @param  motion_x - optical x-axis offset data
 * @param  motion_y - optical y-axis offset data
 */
void ppt_trans_pkt_ctrl_report_nack_motion(uint16_t motion_x, uint16_t motion_y);

/**
 * @brief   get the sequence number of packet
 * @return  sequence number of packet
 */
uint8_t ppt_trans_pkt_ctrl_get_cur_seq(void);

/**
 * @brief  Get current packet control module uint32_t packet sequence
 * @return  uint32_t sequence number of packet
 */
uint32_t ppt_trans_pkt_ctrl_get_u32_seq(void);

/******************************************************************
 * @brief  handle packet send fail compensation
 */
void ppt_trans_pkt_ctrl_report_send_fail_pkt(void);

/**
 * @brief  check whether wheel queue is empty.
 * @return the check result of wheel queue.
 * @retval bool
 */
bool ppt_trans_pkt_ctrl_get_wheel_is_send_cmpl(void);
#endif // PPT_TRANS_FEATURE_PKT_RETRANS_EN

#ifdef __cplusplus
}
#endif      /* __cplusplus */

#endif // __PPT_TRANS_PKT_CTRL_H__
```
